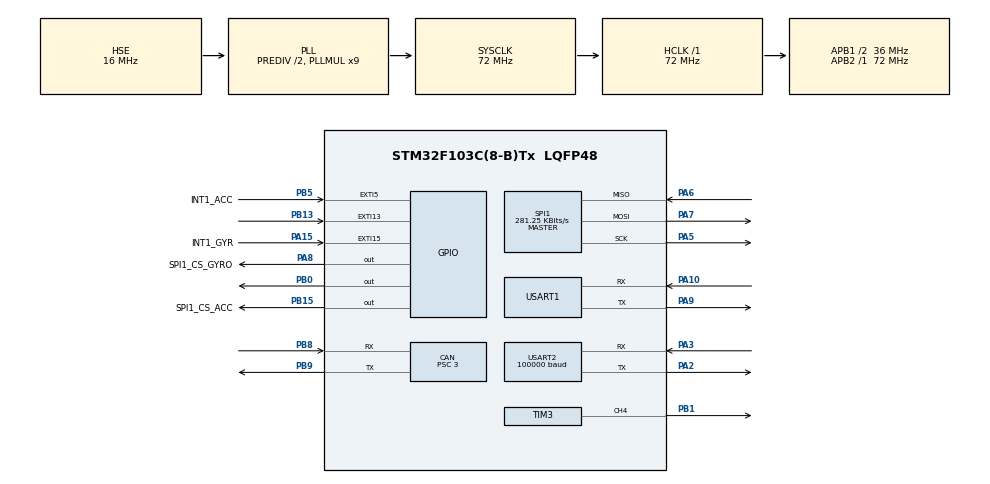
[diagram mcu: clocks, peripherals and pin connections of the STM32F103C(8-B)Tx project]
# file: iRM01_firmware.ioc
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CAN.BS1=CAN_BS1_10TQ
CAN.CalculateBaudRate=999999
CAN.CalculateTimeBit=1000
CAN.CalculateTimeQuantum=83.33333333333334
CAN.Prescaler=3
Dma.Request0=SPI1_RX
Dma.Request1=SPI1_TX
Dma.Request2=USART1_RX
Dma.Request3=USART1_TX
Dma.Request4=USART2_RX
Dma.SPI1_RX.0.Direction=DMA_PERIPH_TO_MEMORY
Dma.SPI1_RX.0.Instance=DMA1_Channel2
Dma.SPI1_RX.0.MemDataAlignment=DMA_MDATAALIGN_BYTE
Dma.SPI1_RX.0.MemInc=DMA_MINC_ENABLE
Dma.SPI1_RX.0.Mode=DMA_NORMAL
Dma.SPI1_RX.0.PeriphDataAlignment=DMA_PDATAALIGN_BYTE
Dma.SPI1_RX.0.PeriphInc=DMA_PINC_DISABLE
Dma.SPI1_RX.0.Priority=DMA_PRIORITY_HIGH
Dma.SPI1_TX.1.Direction=DMA_MEMORY_TO_PERIPH
Dma.SPI1_TX.1.Instance=DMA1_Channel3
Dma.SPI1_TX.1.MemDataAlignment=DMA_MDATAALIGN_BYTE
Dma.SPI1_TX.1.MemInc=DMA_MINC_ENABLE
Dma.SPI1_TX.1.Mode=DMA_NORMAL
Dma.SPI1_TX.1.PeriphDataAlignment=DMA_PDATAALIGN_BYTE
Dma.SPI1_TX.1.PeriphInc=DMA_PINC_DISABLE
Dma.SPI1_TX.1.Priority=DMA_PRIORITY_HIGH
Dma.USART1_RX.2.Direction=DMA_PERIPH_TO_MEMORY
Dma.USART1_RX.2.Instance=DMA1_Channel5
Dma.USART1_RX.2.MemDataAlignment=DMA_MDATAALIGN_BYTE
Dma.USART1_RX.2.MemInc=DMA_MINC_ENABLE
Dma.USART1_RX.2.Mode=DMA_NORMAL
Dma.USART1_RX.2.PeriphDataAlignment=DMA_PDATAALIGN_BYTE
Dma.USART1_RX.2.PeriphInc=DMA_PINC_DISABLE
Dma.USART1_RX.2.Priority=DMA_PRIORITY_LOW
Dma.USART1_TX.3.Direction=DMA_MEMORY_TO_PERIPH
Dma.USART1_TX.3.Instance=DMA1_Channel4
Dma.USART1_TX.3.MemDataAlignment=DMA_MDATAALIGN_BYTE
Dma.USART1_TX.3.MemInc=DMA_MINC_ENABLE
Dma.USART1_TX.3.Mode=DMA_NORMAL
Dma.USART1_TX.3.PeriphDataAlignment=DMA_PDATAALIGN_BYTE
Dma.USART1_TX.3.PeriphInc=DMA_PINC_DISABLE
Dma.USART1_TX.3.Priority=DMA_PRIORITY_LOW
Dma.USART2_RX.4.Direction=DMA_PERIPH_TO_MEMORY
Dma.USART2_RX.4.Instance=DMA1_Channel6
Dma.USART2_RX.4.MemDataAlignment=DMA_MDATAALIGN_BYTE
Dma.USART2_RX.4.MemInc=DMA_MINC_ENABLE
Dma.USART2_RX.4.Mode=DMA_NORMAL
Dma.USART2_RX.4.PeriphDataAlignment=DMA_PDATAALIGN_BYTE
Dma.USART2_RX.4.PeriphInc=DMA_PINC_DISABLE
Dma.USART2_RX.4.Priority=DMA_PRIORITY_HIGH
FREERTOS.Tasks01=defaultTask,24,128,DefaultTaskStart,Default,NULL,Dynamic,NULL,NULL;ledTask,24,128,ledTaskStart,Default,NULL,Dynamic,NULL,NULL;imuTask,24,128,imuTaskStart,Default,NULL,Dynamic,NULL,NULL;chassisTask,24,128,chassisTaskStart,Default,NULL,Dynamic,NULL,NULL
FREERTOS.configUSE_NEWLIB_REENTRANT=1
Mcu.Family=STM32F1
Mcu.Name=STM32F103C(8-B)Tx
Mcu.Package=LQFP48
NVIC.DMA1_Channel2_IRQn=true\:5\:0\:false\:false\:true\:true\:false\:true\:true
NVIC.DMA1_Channel3_IRQn=true\:5\:0\:false\:false\:true\:true\:false\:true\:true
NVIC.DMA1_Channel4_IRQn=true\:5\:0\:false\:false\:true\:true\:false\:true\:true
NVIC.DMA1_Channel5_IRQn=true\:5\:0\:false\:false\:true\:true\:false\:true\:true
NVIC.DMA1_Channel6_IRQn=true\:5\:0\:false\:false\:true\:true\:false\:true\:true
NVIC.EXTI15_10_IRQn=true\:5\:0\:false\:false\:true\:true\:true\:true\:true
NVIC.EXTI9_5_IRQn=true\:5\:0\:false\:false\:true\:true\:true\:true\:true
NVIC.PriorityGroup=NVIC_PRIORITYGROUP_4
NVIC.SPI1_IRQn=true\:5\:0\:false\:false\:true\:true\:true\:true\:true
NVIC.USART1_IRQn=true\:5\:0\:false\:false\:true\:true\:true\:true\:true
NVIC.USART2_IRQn=true\:5\:0\:false\:false\:true\:true\:true\:true\:true
NVIC.USB_HP_CAN1_TX_IRQn=true\:5\:0\:false\:false\:true\:true\:true\:true\:true
NVIC.USB_LP_CAN1_RX0_IRQn=true\:5\:0\:false\:false\:true\:true\:true\:true\:true
PA10.Mode=Asynchronous
PA10.Signal=USART1_RX
PA13.Mode=Trace_Asynchronous_SW
PA13.Signal=SYS_JTMS-SWDIO
PA14.Mode=Trace_Asynchronous_SW
PA14.Signal=SYS_JTCK-SWCLK
PA15.GPIO_Label=INT1_GYR
PA15.Signal=GPXTI15
PA2.Mode=Asynchronous
PA2.Signal=USART2_TX
PA3.GPIO_PuPd=GPIO_PULLUP
PA3.Mode=Asynchronous
PA3.Signal=USART2_RX
PA5.Mode=Full_Duplex_Master
PA5.Signal=SPI1_SCK
PA6.Mode=Full_Duplex_Master
PA6.Signal=SPI1_MISO
PA7.Mode=Full_Duplex_Master
PA7.Signal=SPI1_MOSI
PA8.GPIO_Label=SPI1_CS_GYRO
PA8.GPIO_Speed=GPIO_SPEED_FREQ_LOW
PA8.PinState=GPIO_PIN_RESET
PA8.Signal=GPIO_Output
PA9.Mode=Asynchronous
PA9.Signal=USART1_TX
PB0.Signal=GPIO_Output
PB1.Signal=S_TIM3_CH4
PB13.GPIO_PuPd=GPIO_PULLUP
PB13.Signal=GPXTI13
PB15.GPIO_Label=SPI1_CS_ACC
PB15.Signal=GPIO_Output
PB3.Mode=Trace_Asynchronous_SW
PB3.Signal=SYS_JTDO-TRACESWO
PB5.GPIO_Label=INT1_ACC
PB5.Signal=GPXTI5
PB8.Mode=CAN_Activate
PB8.Signal=CAN_RX
PB9.Mode=CAN_Activate
PB9.Signal=CAN_TX
PD0-OSC_IN.Mode=HSE-External-Oscillator
PD0-OSC_IN.Signal=RCC_OSC_IN
PD1-OSC_OUT.Mode=HSE-External-Oscillator
PD1-OSC_OUT.Signal=RCC_OSC_OUT
ProjectManager.HeapSize=0x200
ProjectManager.StackSize=0x400
ProjectManager.TargetToolchain=STM32CubeIDE
RCC.AHBFreq_Value=72000000
RCC.APB1CLKDivider=RCC_HCLK_DIV2
RCC.APB1Freq_Value=36000000
RCC.APB1TimFreq_Value=72000000
RCC.APB2Freq_Value=72000000
RCC.APB2TimFreq_Value=72000000
RCC.HCLKFreq_Value=72000000
RCC.HSEDivPLL=RCC_HSE_PREDIV_DIV2
RCC.HSE_VALUE=16000000
RCC.PLLMUL=RCC_PLL_MUL9
RCC.PLLSourceVirtual=RCC_PLLSOURCE_HSE
RCC.SYSCLKFreq_VALUE=72000000
RCC.SYSCLKSource=RCC_SYSCLKSOURCE_PLLCLK
RCC.USBFreq_Value=72000000
SH.S_TIM3_CH4.0=TIM3_CH4,PWM Generation4 CH4
SPI1.BaudRatePrescaler=SPI_BAUDRATEPRESCALER_256
SPI1.CLKPhase=SPI_PHASE_1EDGE
SPI1.CLKPolarity=SPI_POLARITY_LOW
SPI1.CalculateBaudRate=281.25 KBits/s
SPI1.Direction=SPI_DIRECTION_2LINES
SPI1.Mode=SPI_MODE_MASTER
SPI1.VirtualType=VM_MASTER
TIM3.Channel-PWM\ Generation4\ CH4=TIM_CHANNEL_4
TIM3.Period=100-1
TIM3.Prescaler=3600-1
USART1.VirtualMode=VM_ASYNC
USART2.BaudRate=100000
USART2.Mode=MODE_RX
USART2.VirtualMode=VM_ASYNC
USART2.WordLength=WORDLENGTH_9B
VP_FREERTOS_VS_CMSIS_V2.Mode=CMSIS_V2
board=custom

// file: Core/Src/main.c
/* USER CODE BEGIN Header */
/**
  ******************************************************************************
  * @file           : main.c
  * @brief          : Main program body
  ******************************************************************************
  * @attention
  *
  * Copyright (c) 2023 STMicroelectronics.
  * All rights reserved.
  *
  * This software is licensed under terms that can be found in the LICENSE file
  * in the root directory of this software component.
  * If no LICENSE file comes with this software, it is provided AS-IS.
  *
  ******************************************************************************
  */
/* USER CODE END Header */
#include "main.h"
#include "cmsis_os.h"
#include "can.h"
#include "dma.h"
#include "spi.h"
#include "tim.h"
#include "usart.h"
#include "gpio.h"

/* USER CODE BEGIN Includes */
#include "../../Libraries/Inc/BMI088.h"
/* USER CODE END Includes */

/* USER CODE BEGIN PV */
//BMI088 imu;
//SPI_HandleTypeDef hspi1;
/* USER CODE END PV */

void SystemClock_Config(void);
void MX_FREERTOS_Init(void);

/* USER CODE BEGIN 0 */
//void HAL_SPI_TxRxCpltCallback(SPI_HandleTypeDef *hspi) {
//
//	if (hspi->Instance == SPI1) {
//
//		if (imu.readingAcc) {
//
//			BMI088_ReadAccelerometerDMA_Complete(&imu);
//
//			/* Filter accelerometer data */
//		//	RCFilter_Update(&lpfAcc[0], imu.acc_mps2[0]);
//		//	RCFilter_Update(&lpfAcc[1], imu.acc_mps2[1]);
//		//	RCFilter_Update(&lpfAcc[2], imu.acc_mps2[2]);
//
//		}
//
//		if (imu.readingGyr) {
//
//			BMI088_ReadGyroscopeDMA_Complete(&imu);
//
//			/* Filter gyroscope data */
//		//	RCFilter_Update(&lpfGyr[0], imu.gyr_rps[0]);
//		//	RCFilter_Update(&lpfGyr[1], imu.gyr_rps[1]);
//		//	RCFilter_Update(&lpfGyr[2], imu.gyr_rps[2]);
//
//		}
//
//	}
//
//}
//
//void HAL_GPIO_EXTI_Callback(uint16_t GPIO_Pin) {
//
//	if (GPIO_Pin == INT1_ACC_Pin) {
//
//		BMI088_ReadAccelerometerDMA(&imu);
//
//	} else if (GPIO_Pin == INT1_GYR_Pin) {
//
//		BMI088_ReadGyroscopeDMA(&imu);
//
//	}
//
//}
/* USER CODE END 0 */

int main(void)
{

  /* MCU Configuration--------------------------------------------------------*/

  /* Reset of all peripherals, Initializes the Flash interface and the Systick. */
  HAL_Init();

  /* Configure the system clock */
  SystemClock_Config();

  /* Initialize all configured peripherals */
  MX_GPIO_Init();
  MX_DMA_Init();
  MX_TIM3_Init();
  MX_SPI1_Init();
  MX_USART1_UART_Init();
  MX_CAN_Init();
  MX_USART2_UART_Init();
  /* USER CODE BEGIN 2 */
  HAL_TIM_PWM_Start(&htim3, TIM_CHANNEL_4);
  /* USER CODE END 2 */

  /* Init scheduler */
  osKernelInitialize();  /* Call init function for freertos objects (in freertos.c) */
  MX_FREERTOS_Init();

  /* Start scheduler */
  osKernelStart();

  /* We should never get here as control is now taken by the scheduler */
  /* Infinite loop */
  while (1)
  {

  }
}

void SystemClock_Config(void)
{
  RCC_OscInitTypeDef RCC_OscInitStruct = {0};
  RCC_ClkInitTypeDef RCC_ClkInitStruct = {0};

  /** Initializes the RCC Oscillators according to the specified parameters
  * in the RCC_OscInitTypeDef structure.
  */
  RCC_OscInitStruct.OscillatorType = RCC_OSCILLATORTYPE_HSE;
  RCC_OscInitStruct.HSEState = RCC_HSE_ON;
  RCC_OscInitStruct.HSEPredivValue = RCC_HSE_PREDIV_DIV2;
  RCC_OscInitStruct.HSIState = RCC_HSI_ON;
  RCC_OscInitStruct.PLL.PLLState = RCC_PLL_ON;
  RCC_OscInitStruct.PLL.PLLSource = RCC_PLLSOURCE_HSE;
  RCC_OscInitStruct.PLL.PLLMUL = RCC_PLL_MUL9;
  if (HAL_RCC_OscConfig(&RCC_OscInitStruct) != HAL_OK)
  {
    Error_Handler();
  }

  /** Initializes the CPU, AHB and APB buses clocks
  */
  RCC_ClkInitStruct.ClockType = RCC_CLOCKTYPE_HCLK|RCC_CLOCKTYPE_SYSCLK
                              |RCC_CLOCKTYPE_PCLK1|RCC_CLOCKTYPE_PCLK2;
  RCC_ClkInitStruct.SYSCLKSource = RCC_SYSCLKSOURCE_PLLCLK;
  RCC_ClkInitStruct.AHBCLKDivider = RCC_SYSCLK_DIV1;
  RCC_ClkInitStruct.APB1CLKDivider = RCC_HCLK_DIV2;
  RCC_ClkInitStruct.APB2CLKDivider = RCC_HCLK_DIV1;

  if (HAL_RCC_ClockConfig(&RCC_ClkInitStruct, FLASH_LATENCY_2) != HAL_OK)
  {
    Error_Handler();
  }
}

void Error_Handler(void)
{
  __disable_irq();
  while (1)
  {
  }
}

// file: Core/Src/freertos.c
/* USER CODE BEGIN Header */
/**
  ******************************************************************************
  * File Name          : freertos.c
  * Description        : Code for freertos applications
  ******************************************************************************
  * @attention
  *
  * Copyright (c) 2023 STMicroelectronics.
  * All rights reserved.
  *
  * This software is licensed under terms that can be found in the LICENSE file
  * in the root directory of this software component.
  * If no LICENSE file comes with this software, it is provided AS-IS.
  *
  ******************************************************************************
  */
/* USER CODE END Header */

#include "FreeRTOS.h"
#include "task.h"
#include "main.h"
#include "cmsis_os.h"

/* USER CODE BEGIN Variables */
//BMI088 imu;
//SPI_HandleTypeDef hspi1;
/* USER CODE END Variables */
/* Definitions for defaultTask */
osThreadId_t defaultTaskHandle;
const osThreadAttr_t defaultTask_attributes = {
  .name = "defaultTask",
  .stack_size = 128 * 4,
  .priority = (osPriority_t) osPriorityNormal,
};
/* Definitions for ledTask */
osThreadId_t ledTaskHandle;
const osThreadAttr_t ledTask_attributes = {
  .name = "ledTask",
  .stack_size = 128 * 4,
  .priority = (osPriority_t) osPriorityNormal,
};
/* Definitions for imuTask */
osThreadId_t imuTaskHandle;
const osThreadAttr_t imuTask_attributes = {
  .name = "imuTask",
  .stack_size = 128 * 4,
  .priority = (osPriority_t) osPriorityNormal,
};
/* Definitions for chassisTask */
osThreadId_t chassisTaskHandle;
const osThreadAttr_t chassisTask_attributes = {
  .name = "chassisTask",
  .stack_size = 128 * 4,
  .priority = (osPriority_t) osPriorityNormal,
};

/* USER CODE BEGIN FunctionPrototypes */
__weak void RTOS_Init(void) {}
__weak void RTOS_Default_Task(const void *argument) { UNUSED(argument); }
__weak void imuTask(const void *argument) { UNUSED(argument); }
__weak void ledTask(const void *argument) { UNUSED(argument); }
__weak void chassisTask(const void *argument) { UNUSED(argument); }
/* USER CODE END FunctionPrototypes */

void DefaultTaskStart(void *argument);
void ledTaskStart(void *argument);
void imuTaskStart(void *argument);
void chassisTaskStart(void *argument);

void MX_FREERTOS_Init(void); /* (MISRA C 2004 rule 8.1) */

void MX_FREERTOS_Init(void) {
  /* USER CODE BEGIN Init */
	RTOS_Init();
  /* USER CODE END Init */

  /* Create the thread(s) */
  /* creation of defaultTask */
  defaultTaskHandle = osThreadNew(DefaultTaskStart, NULL, &defaultTask_attributes);

  /* creation of ledTask */
  ledTaskHandle = osThreadNew(ledTaskStart, NULL, &ledTask_attributes);

  /* creation of imuTask */
  imuTaskHandle = osThreadNew(imuTaskStart, NULL, &imuTask_attributes);

  /* creation of chassisTask */
  chassisTaskHandle = osThreadNew(chassisTaskStart, NULL, &chassisTask_attributes);

}

void DefaultTaskStart(void *argument)
{
  /* USER CODE BEGIN DefaultTaskStart */
	RTOS_Default_Task(argument);
  /* Infinite loop */
  for(;;)
  {
    osDelay(1);
  }
  /* USER CODE END DefaultTaskStart */
}

void ledTaskStart(void *argument)
{
  /* USER CODE BEGIN ledTaskStart */
	ledTask(argument);
  /* Infinite loop */

  for(;;)
  {
    osDelay(1);
  }
  /* USER CODE END ledTaskStart */
}

void imuTaskStart(void *argument)
{
  /* USER CODE BEGIN imuTaskStart */
	imuTask(argument);
  /* Infinite loop */
  for(;;)
  {
    osDelay(1);
  }
  /* USER CODE END imuTaskStart */
}

void chassisTaskStart(void *argument)
{
  /* USER CODE BEGIN chassisTaskStart */
	chassisTask(argument);
  /* Infinite loop */
  for(;;)
  {
    osDelay(1);
  }
  /* USER CODE END chassisTaskStart */
}
